# LM3S6110 register map
File version: 7944
ARM Cortex-M3 Stellaris Device
Registers are 32-bit, read-write, no defined reset value unless marked. A register's access mark holds for its fields unless they carry their own. Offsets are from the block's base; lines under a group give offsets from that group; [hi:lo] are bit positions; {n}, {i} and the like mark numbered series; 'fields as' and 'values as' point back to an identical list; <NAME> marks a mode.

## Memory map
0x40000000 WATCHDOG0 size 0x1000 — Register map for WATCHDOG0 peripheral
0x40004000 GPIO_PORTA size 0x1000 — Register map for GPIO_PORTA peripheral
0x40005000 GPIO_PORTB size 0x1000
0x40006000 GPIO_PORTC size 0x1000
0x40007000 GPIO_PORTD size 0x1000
0x40008000 SSI0 size 0x1000 — Register map for SSI0 peripheral
0x4000C000 UART0 size 0x1000 — Register map for UART0 peripheral
0x40024000 GPIO_PORTE size 0x1000
0x40025000 GPIO_PORTF size 0x1000
0x40026000 GPIO_PORTG size 0x1000
0x40028000 PWM0 size 0x1000 — Register map for PWM0 peripheral
0x40030000 TIMER0 size 0x1000 — Register map for TIMER0 peripheral
0x40031000 TIMER1 size 0x1000
0x40032000 TIMER2 size 0x1000
0x4003C000 COMP size 0x1000 — Register map for COMP peripheral
0x40048000 MAC size 0x1000 — Register map for MAC peripheral
0x400FD000 FLASH_CTRL blocks up to offset 0x2000 — Register map for FLASH_CTRL peripheral
0x400FE000 SYSCTL size 0x1000 — Register map for SYSCTL peripheral
0xE000E000 NVIC size 0x1000 — Register map for NVIC peripheral

## Further device data
memory: FLASH description=FLASH Memory Map for lm3s6110 baseAddress=0x00000000
  offset=0 size=0x00010000 usage=FLASH Memory
memory: SRAM description=SRAM Memory Map for lm3s6110 baseAddress=0x20000000
  offset=0 size=0x00004000 usage=SRAM

## WATCHDOG0 — Register map for WATCHDOG0 peripheral
Base 0x40000000; register names take the prefix WATCHDOG0
0x00 LOAD — Watchdog Load
  [31:0] WDT_LOAD — Watchdog Load Value
0x04 VALUE — Watchdog Value
  [31:0] WDT_VALUE
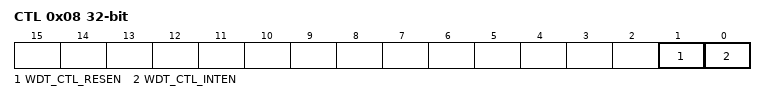
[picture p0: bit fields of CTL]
0x08 CTL — Watchdog Control
  [1] WDT_CTL_RESEN — Watchdog Reset Enable
  [0] WDT_CTL_INTEN — Watchdog Interrupt Enable
0x0C ICR wo — Watchdog Interrupt Clear
  [31:0] WDT_ICR
0x10 RIS — Watchdog Raw Interrupt Status
  [0] WDT_RIS_WDTRIS
0x14 MIS — Watchdog Masked Interrupt Status
  [0] WDT_MIS_WDTMIS
0x418 TEST — Watchdog Test
  [8] WDT_TEST_STALL — Watchdog Stall Enable
0xC00 LOCK — Watchdog Lock
  [31:0] WDT_LOCK
    0=WDT_LOCK_UNLOCKED (Unlocked); 1=WDT_LOCK_LOCKED (Locked); 0x1ACCE551=WDT_LOCK_UNLOCK (Unlocks the watchdog timer)

## GPIO_PORTA — Register map for GPIO_PORTA peripheral
Base 0x40004000; register names take the prefix GPIO_PORTA
Same registers: GPIO_PORTB 0x40005000 (register names take the prefix GPIO_PORTB), GPIO_PORTC 0x40006000 (register names take the prefix GPIO_PORTC), GPIO_PORTD 0x40007000 (register names take the prefix GPIO_PORTD), GPIO_PORTE 0x40024000 (register names take the prefix GPIO_PORTE), GPIO_PORTF 0x40025000 (register names take the prefix GPIO_PORTF), GPIO_PORTG 0x40026000 (register names take the prefix GPIO_PORTG)
0x3FC DATA — GPIO Data
0x400 DIR — GPIO Direction
0x404 IS — GPIO Interrupt Sense
0x408 IBE — GPIO Interrupt Both Edges
0x40C IEV — GPIO Interrupt Event
0x410 IM — GPIO Interrupt Mask
0x414 RIS — GPIO Raw Interrupt Status
0x418 MIS — GPIO Masked Interrupt Status
0x41C ICR wo — GPIO Interrupt Clear
0x420 AFSEL — GPIO Alternate Function Select
0x500 DR2R — GPIO 2-mA Drive Select
0x504 DR4R — GPIO 4-mA Drive Select
0x508 DR8R — GPIO 8-mA Drive Select
0x50C ODR — GPIO Open Drain Select
0x510 PUR — GPIO Pull-Up Select
0x514 PDR — GPIO Pull-Down Select
0x518 SLR — GPIO Slew Rate Control Select
0x51C DEN — GPIO Digital Enable
0x520 LOCK — GPIO Lock
  [31:0] GPIO_LOCK
    0=GPIO_LOCK_UNLOCKED (The GPIOCR register is unlocked and may be modified); 1=GPIO_LOCK_LOCKED (The GPIOCR register is locked and may not be modified); 0x1ACCE551=GPIO_LOCK_KEY (Unlocks the GPIO_CR register)
0x524 CR ro — GPIO Commit

## SSI0 — Register map for SSI0 peripheral
Base 0x40008000; register names take the prefix SSI0
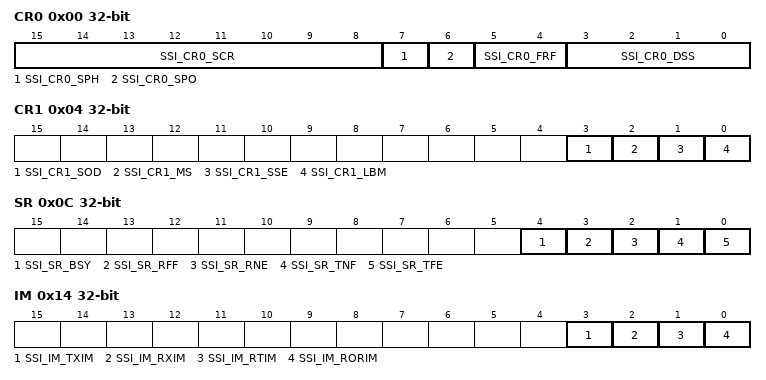
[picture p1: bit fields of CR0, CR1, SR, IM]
0x00 CR0 — SSI Control 0
  [15:8] SSI_CR0_SCR — SSI Serial Clock Rate
  [7] SSI_CR0_SPH — SSI Serial Clock Phase
  [6] SSI_CR0_SPO — SSI Serial Clock Polarity
  [5:4] SSI_CR0_FRF — SSI Frame Format Select
    0=SSI_CR0_FRF_MOTO (Freescale SPI Frame Format); 1=SSI_CR0_FRF_TI (Texas Instruments Synchronous Serial Frame Format); 2=SSI_CR0_FRF_NMW (MICROWIRE Frame Format)
  [3:0] SSI_CR0_DSS — SSI Data Size Select
    {v}={v+1}-bit data (v=3..15)
0x04 CR1 — SSI Control 1
  [3] SSI_CR1_SOD — SSI Slave Mode Output Disable
  [2] SSI_CR1_MS — SSI Master/Slave Select
  [1] SSI_CR1_SSE — SSI Synchronous Serial Port Enable
  [0] SSI_CR1_LBM — SSI Loopback Mode
0x08 DR — SSI Data
  [15:0] SSI_DR_DATA — SSI Receive/Transmit Data
0x0C SR — SSI Status
  [4] SSI_SR_BSY — SSI Busy Bit
  [3] SSI_SR_RFF — SSI Receive FIFO Full
  [2] SSI_SR_RNE — SSI Receive FIFO Not Empty
  [1] SSI_SR_TNF — SSI Transmit FIFO Not Full
  [0] SSI_SR_TFE — SSI Transmit FIFO Empty
0x10 CPSR — SSI Clock Prescale
  [7:0] SSI_CPSR_CPSDVSR — SSI Clock Prescale Divisor
0x14 IM — SSI Interrupt Mask
  [3] SSI_IM_TXIM — SSI Transmit FIFO Interrupt Mask
  [2] SSI_IM_RXIM — SSI Receive FIFO Interrupt Mask
  [1] SSI_IM_RTIM — SSI Receive Time-Out Interrupt Mask
  [0] SSI_IM_RORIM — SSI Receive Overrun Interrupt Mask
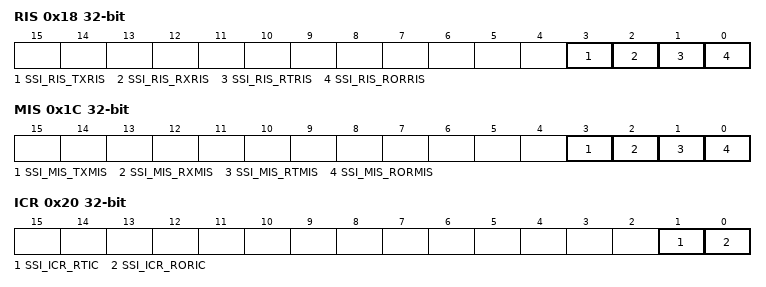
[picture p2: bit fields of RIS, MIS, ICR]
0x18 RIS — SSI Raw Interrupt Status
  [3] SSI_RIS_TXRIS — SSI Transmit FIFO Raw Interrupt Status
  [2] SSI_RIS_RXRIS — SSI Receive FIFO Raw Interrupt Status
  [1] SSI_RIS_RTRIS — SSI Receive Time-Out Raw Interrupt Status
  [0] SSI_RIS_RORRIS — SSI Receive Overrun Raw Interrupt Status
0x1C MIS — SSI Masked Interrupt Status
  [3] SSI_MIS_TXMIS — SSI Transmit FIFO Masked Interrupt Status
  [2] SSI_MIS_RXMIS — SSI Receive FIFO Masked Interrupt Status
  [1] SSI_MIS_RTMIS — SSI Receive Time-Out Masked Interrupt Status
  [0] SSI_MIS_RORMIS — SSI Receive Overrun Masked Interrupt Status
0x20 ICR wo — SSI Interrupt Clear
  [1] SSI_ICR_RTIC — SSI Receive Time-Out Interrupt Clear
  [0] SSI_ICR_RORIC — SSI Receive Overrun Interrupt Clear
